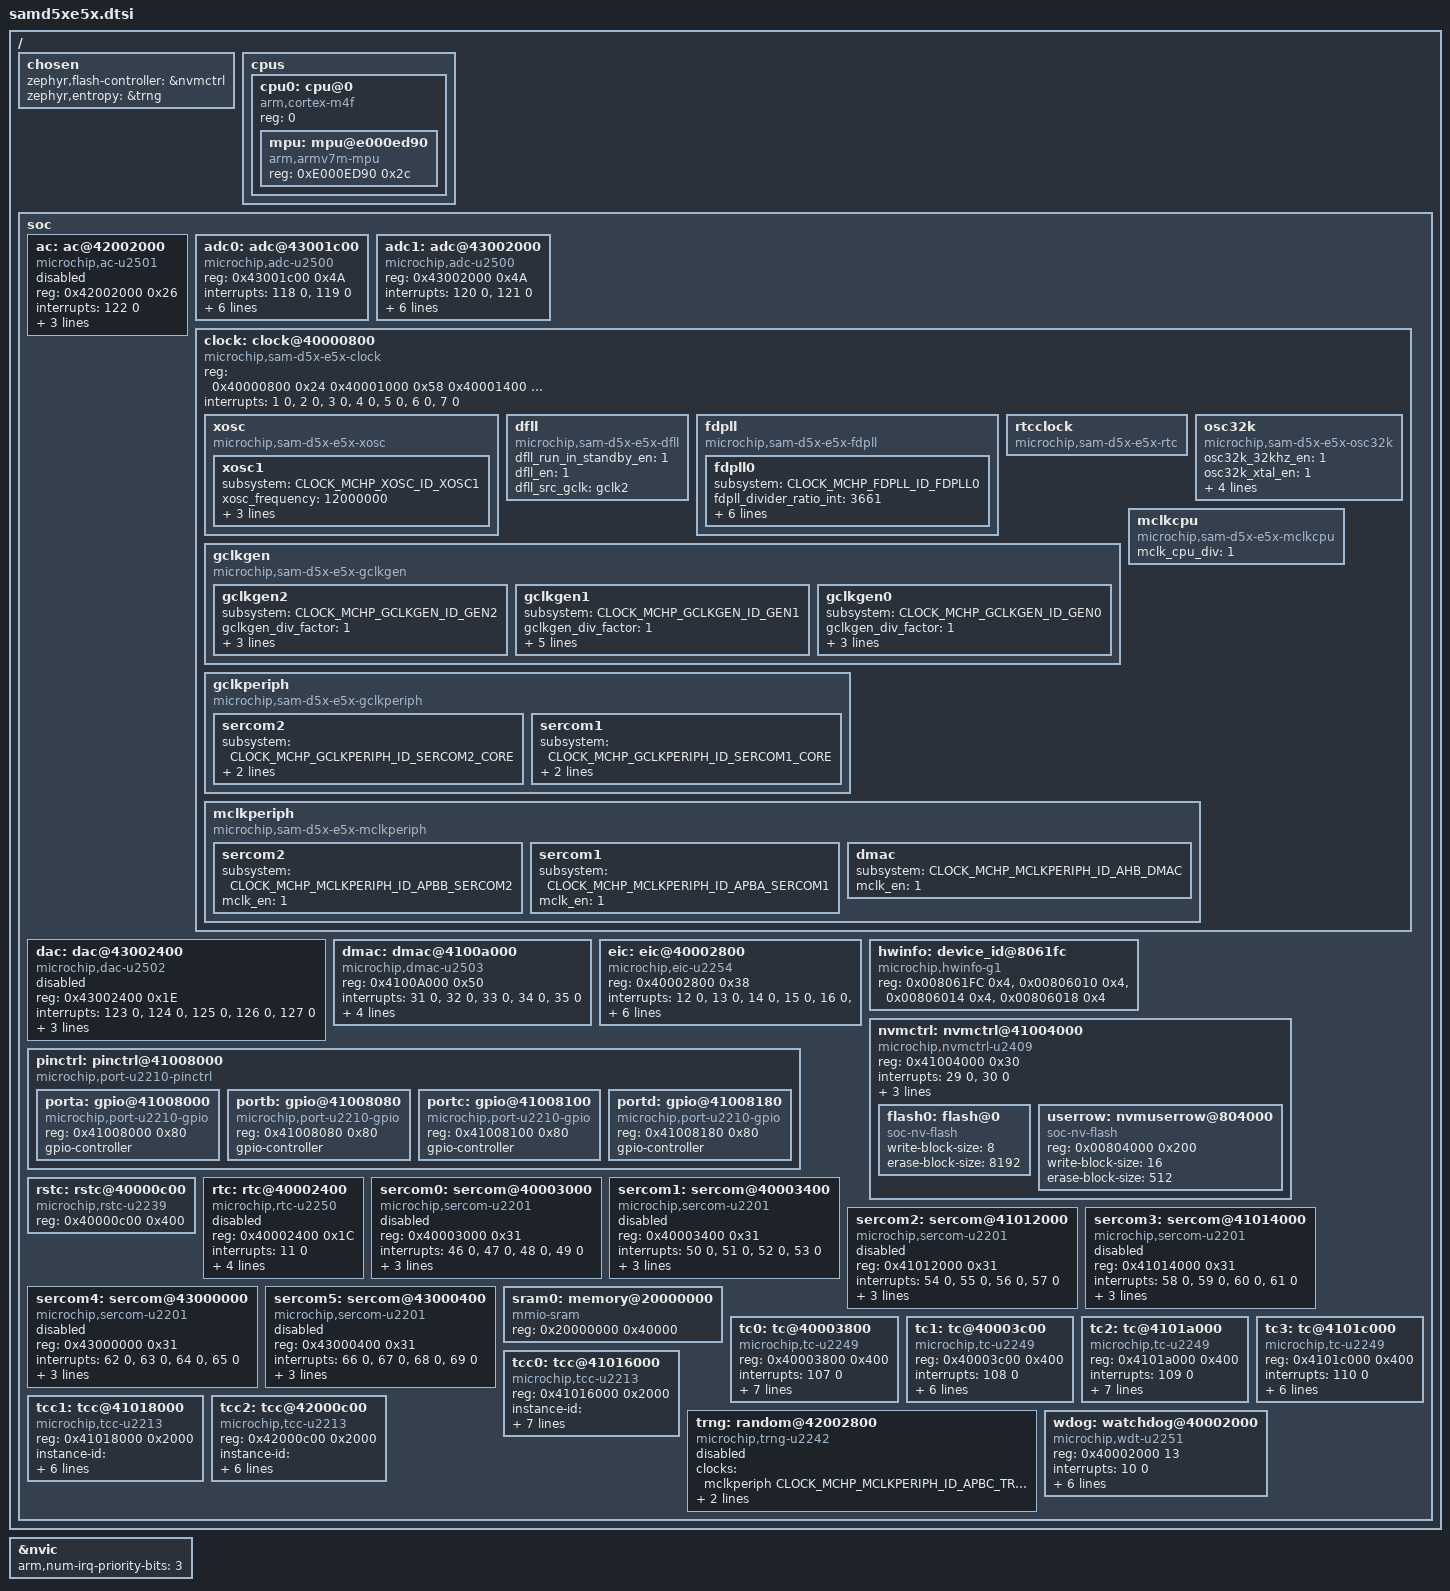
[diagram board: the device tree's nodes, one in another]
/*
 * Copyright (c) 2025 Microchip Technology Inc.
 *
 * SPDX-License-Identifier: Apache-2.0
 */

#include <arm/armv7-m.dtsi>
#include <zephyr/dt-bindings/adc/adc.h>
#include <zephyr/dt-bindings/gpio/gpio.h>
#include <zephyr/dt-bindings/i2c/i2c.h>
#include <zephyr/dt-bindings/pwm/pwm.h>
#include <zephyr/dt-bindings/pwm/mchp_pwm_sam_d5x_e5x.h>
#include <zephyr/dt-bindings/clock/mchp_sam_d5x_e5x_clock.h>
/ {
	chosen {
		zephyr,flash-controller = &nvmctrl;
		zephyr,entropy = &trng;
	};
	cpus {
		#address-cells = <1>;
		#size-cells = <0>;
		cpu0: cpu@0 {
			device_type = "cpu";
			compatible = "arm,cortex-m4f";
			reg = <0>;
			#address-cells = <1>;
			#size-cells = <1>;
			mpu: mpu@e000ed90 {
				compatible = "arm,armv7m-mpu";
				reg = <0xE000ED90 0x2c>;
			};
		};
	};
	/* Child nodes inside this block are arranged alphabetically */
	soc {
		ac: ac@42002000 {
			compatible = "microchip,ac-u2501";
			status = "disabled";
			reg = <0x42002000 0x26>;
			interrupts = <122 0>;
			clocks = <&mclkperiph CLOCK_MCHP_MCLKPERIPH_ID_APBC_AC>,
					<&gclkperiph CLOCK_MCHP_GCLKPERIPH_ID_AC>;
			clock-names = "mclk", "gclk";
		};
		adc0: adc@43001c00 {
			compatible = "microchip,adc-u2500";
			reg = <0x43001c00 0x4A>;
			interrupts = <118 0>, <119 0>;
			interrupt-names = "overrun", "resrdy";
			/*
			 * 16 MHz max, source clock must not exceed 100 MHz.
			 * -> 48 MHz GCLK(2) / 4 = 12 MHz
			 */
			prescaler = <4>;
			num-channels = <23>;
			/* Internal Bandgap reference voltage */
			vref-mv = <2400>;
			#io-channel-cells = <1>;
			clocks = <&mclkperiph CLOCK_MCHP_MCLKPERIPH_ID_APBD_ADC0>,
					<&gclkperiph CLOCK_MCHP_GCLKPERIPH_ID_ADC0>;
			clock-names = "MCLK", "GCLK";
		};
		adc1: adc@43002000 {
			compatible = "microchip,adc-u2500";
			reg = <0x43002000 0x4A>;
			interrupts = <120 0>, <121 0>;
			interrupt-names = "overrun", "resrdy";
			/*
			 * 16 MHz max, source clock must not exceed 100 MHz.
			 * -> 48 MHz GCLK(2) / 4 = 12 MHz
			 */
			prescaler = <4>;
			num-channels = <23>;
			/* Internal Bandgap reference voltage */
			vref-mv = <2400>;
			#io-channel-cells = <1>;
			clocks = <&mclkperiph CLOCK_MCHP_MCLKPERIPH_ID_APBD_ADC1>,
					<&gclkperiph CLOCK_MCHP_GCLKPERIPH_ID_ADC1>;
			clock-names = "MCLK", "GCLK";
		};
		clock: clock@40000800 {
			compatible = "microchip,sam-d5x-e5x-clock";
			reg =	<
					0x40000800 0x24
					0x40001000 0x58
					0x40001400 0x20
					0x40001c00 0x140>; // mclk, oscctrl, osc32kctrl, gclk
			interrupts = <1 0>, <2 0>, <3 0>, <4 0>, <5 0>, <6 0>, <7 0>;

			xosc: xosc {
				compatible = "microchip,sam-d5x-e5x-xosc";
				xosc1 {
					subsystem = <CLOCK_MCHP_XOSC_ID_XOSC1>;
					xosc_frequency = <12000000>;
					xosc_en = <1>;
					xosc_xtal_en = <1>;
					xosc_run_in_standby_en = <1>;
				};
			};
			dfll: dfll {
				compatible = "microchip,sam-d5x-e5x-dfll";
				dfll_run_in_standby_en = <1>;
				dfll_en = <1>;
				dfll_src_gclk = "gclk2";
			};
			fdpll: fdpll {
				compatible = "microchip,sam-d5x-e5x-fdpll";
				fdpll0 {
					subsystem = <CLOCK_MCHP_FDPLL_ID_FDPLL0>;
					fdpll_divider_ratio_int = <3661>;
					fdpll_divider_ratio_frac = <3>;
					fdpll_src = "gclk2";
					fdpll_lock_bypass_en = <1>;
					fdpll_run_in_standby_en = <0>;
					fdpll_en = <1>;
					fdpll_wakeup_fast_en = <1>;
				};
			};
			rtcclock: rtcclock {
				compatible = "microchip,sam-d5x-e5x-rtc";
				#clock-cells = <1>;
			};
			osc32k: osc32k {
				compatible = "microchip,sam-d5x-e5x-osc32k";
				osc32k_32khz_en = <1>;
				osc32k_xtal_en = <1>;
				osc32k_startup_time = <62>;
				osc32k_run_in_standby_en = <1>;
				osc32k_gain_mode = "standard";
				osc32k_en = <1>;
			};
			gclkgen: gclkgen {
				compatible = "microchip,sam-d5x-e5x-gclkgen";
				gclkgen2 {
					subsystem = <CLOCK_MCHP_GCLKGEN_ID_GEN2>;
					gclkgen_div_factor = <1>;
					gclkgen_run_in_standby_en = <1>;
					gclkgen_src = "osc32k";
					gclkgen_en = <1>;
				};
				gclkgen1 {
					subsystem = <CLOCK_MCHP_GCLKGEN_ID_GEN1>;
					gclkgen_div_factor = <1>;
					gclkgen_run_in_standby_en = <1>;
					gclkgen_pin_output_en = <1>;
					gclkgen_src = "xosc1";
					gclkgen_duty_50_50_en = <1>;
					gclkgen_en = <1>;
				};
				gclkgen0 {
					subsystem = <CLOCK_MCHP_GCLKGEN_ID_GEN0>;
					gclkgen_div_factor = <1>;
					gclkgen_run_in_standby_en = <1>;
					gclkgen_src = "fdpll0";
					gclkgen_en = <1>;
				};
			};
			gclkperiph: gclkperiph {
				compatible = "microchip,sam-d5x-e5x-gclkperiph";
				#clock-cells = <1>;
				sercom2 {
					subsystem = <CLOCK_MCHP_GCLKPERIPH_ID_SERCOM2_CORE>;
					gclkperiph_src = "gclk0";
					gclkperiph_en = <1>;
				};
				sercom1 {
					subsystem = <CLOCK_MCHP_GCLKPERIPH_ID_SERCOM1_CORE>;
					gclkperiph_src = "gclk0";
					gclkperiph_en = <1>;
				};
			};
			mclkcpu: mclkcpu {
				compatible = "microchip,sam-d5x-e5x-mclkcpu";
				mclk_cpu_div = <1>;
			};
			mclkperiph: mclkperiph {
				compatible = "microchip,sam-d5x-e5x-mclkperiph";
				#clock-cells = <1>;
				sercom2 {
					subsystem = <CLOCK_MCHP_MCLKPERIPH_ID_APBB_SERCOM2>;
					mclk_en = <1>;
				};
				sercom1 {
					subsystem = <CLOCK_MCHP_MCLKPERIPH_ID_APBA_SERCOM1>;
					mclk_en = <1>;
				};
				dmac {
					subsystem = <CLOCK_MCHP_MCLKPERIPH_ID_AHB_DMAC>;
					mclk_en = <1>;
				};
			};
		};
		dac: dac@43002400 {
			compatible = "microchip,dac-u2502";
			status = "disabled";
			reg = <0x43002400 0x1E>;
			interrupts = <123 0>, <124 0>, <125 0>, <126 0>, <127 0>;
			#io-channel-cells = <1>;
			clocks = <&mclkperiph CLOCK_MCHP_MCLKPERIPH_ID_APBD_DAC>,
					<&gclkperiph CLOCK_MCHP_GCLKPERIPH_ID_DAC>;
			clock-names = "mclk", "gclk";
		};
		dmac: dmac@4100a000 {
			compatible = "microchip,dmac-u2503";
			reg = <0x4100A000 0x50>;
			interrupts = <31 0>, <32 0>, <33 0>, <34 0>, <35 0>;
			clocks = <&mclkperiph CLOCK_MCHP_MCLKPERIPH_ID_AHB_DMAC>;
			clock-names = "mclk";
			dma-channels = <32>;
			dma-alignment = <16>;
			#dma-cells = <2>;
		};
		eic: eic@40002800 {
			compatible = "microchip,eic-u2254";
			status = "okay";
			reg = <0x40002800 0x38>;
			interrupts = <12 0>, <13 0>, <14 0>, <15 0>,
				     <16 0>, <17 0>, <18 0>, <19 0>,
				     <20 0>, <21 0>, <22 0>, <23 0>,
				     <24 0>, <25 0>, <26 0>, <27 0>;
			clocks = <&mclkperiph CLOCK_MCHP_MCLKPERIPH_ID_APBA_EIC>,
					<&gclkperiph CLOCK_MCHP_GCLKPERIPH_ID_EIC>;
			clock-names = "mclk", "gclk";
			low-power-mode;
		};
		hwinfo: device_id@8061fc {
			compatible = "microchip,hwinfo-g1";
			reg =	<0x008061FC 0x4>,
				<0x00806010 0x4>,
				<0x00806014 0x4>,
				<0x00806018 0x4>;
		};
		nvmctrl: nvmctrl@41004000 {
			compatible = "microchip,nvmctrl-u2409";
			status = "okay";
			reg = <0x41004000 0x30>;
			interrupts = <29 0>, <30 0>;
			clocks = <&mclkperiph CLOCK_MCHP_MCLKPERIPH_ID_APBB_NVMCTRL>;
			clock-names = "mclk";
			lock-regions = <32>;
			#address-cells = <1>;
			#size-cells = <1>;
			flash0: flash@0 {
				compatible = "soc-nv-flash";
				write-block-size = <8>;
				erase-block-size = <8192>;
			};
		    userrow: nvmuserrow@804000 {
				compatible = "soc-nv-flash";
				reg = <0x00804000 0x200>;
				write-block-size = <16>;
				erase-block-size = <512>;
			};
		};
		pinctrl: pinctrl@41008000 {
			compatible = "microchip,port-u2210-pinctrl";
			#address-cells = <1>;
			#size-cells = <1>;
			ranges = <0x41008000 0x41008000 0x200>;
			porta: gpio@41008000 {
				compatible = "microchip,port-u2210-gpio";
				reg = <0x41008000 0x80>;
				gpio-controller;
				#gpio-cells = <2>;
				#microchip,pin-cells = <2>;
			};
			portb: gpio@41008080 {
				compatible = "microchip,port-u2210-gpio";
				reg = <0x41008080 0x80>;
				gpio-controller;
				#gpio-cells = <2>;
				#microchip,pin-cells = <2>;
			};
			portc: gpio@41008100 {
				compatible = "microchip,port-u2210-gpio";
				reg = <0x41008100 0x80>;
				gpio-controller;
				#gpio-cells = <2>;
				#microchip,pin-cells = <2>;
			};
			portd: gpio@41008180 {
				compatible = "microchip,port-u2210-gpio";
				reg = <0x41008180 0x80>;
				gpio-controller;
				#gpio-cells = <2>;
				#microchip,pin-cells = <2>;
			};
		};
		rstc: rstc@40000c00 {
			compatible = "microchip,rstc-u2239";
			status = "okay";
			reg = <0x40000c00 0x400>;
		};
		rtc: rtc@40002400 {
			compatible = "microchip,rtc-u2250";
			status = "disabled";
			reg = <0x40002400 0x1C>;
			interrupts = <11 0>;
			clocks = <&mclkperiph CLOCK_MCHP_MCLKPERIPH_ID_APBA_RTC>,
					<&rtcclock CLOCK_MCHP_RTC_ID>;
			clock-names = "mclk", "rtcclk";
			prescaler = <1>;
		};
		sercom0: sercom@40003000 {
			compatible = "microchip,sercom-u2201";
			status = "disabled";
			reg = <0x40003000 0x31>;
			interrupts = <46 0>, <47 0>, <48 0>, <49 0>;
			clocks = <&mclkperiph CLOCK_MCHP_MCLKPERIPH_ID_APBA_SERCOM0>,
					<&gclkperiph CLOCK_MCHP_GCLKPERIPH_ID_SERCOM0_CORE>;
			clock-names = "mclk", "gclk";
		};
		sercom1: sercom@40003400 {
			compatible = "microchip,sercom-u2201";
			status = "disabled";
			reg = <0x40003400 0x31>;
			interrupts = <50 0>, <51 0>, <52 0>, <53 0>;
			clocks = <&mclkperiph CLOCK_MCHP_MCLKPERIPH_ID_APBA_SERCOM1>,
					<&gclkperiph CLOCK_MCHP_GCLKPERIPH_ID_SERCOM1_CORE>;
			clock-names = "mclk", "gclk";
		};
		sercom2: sercom@41012000 {
			compatible = "microchip,sercom-u2201";
			status = "disabled";
			reg = <0x41012000 0x31>;
			interrupts = <54 0>, <55 0>, <56 0>, <57 0>;
			clocks = <&mclkperiph CLOCK_MCHP_MCLKPERIPH_ID_APBB_SERCOM2>,
					<&gclkperiph CLOCK_MCHP_GCLKPERIPH_ID_SERCOM2_CORE>;
			clock-names = "mclk", "gclk";
		};
		sercom3: sercom@41014000 {
			compatible = "microchip,sercom-u2201";
			status = "disabled";
			reg = <0x41014000 0x31>;
			interrupts = <58 0>, <59 0>, <60 0>, <61 0>;
			clocks = <&mclkperiph CLOCK_MCHP_MCLKPERIPH_ID_APBB_SERCOM3>,
					<&gclkperiph CLOCK_MCHP_GCLKPERIPH_ID_SERCOM3_CORE>;
			clock-names = "mclk", "gclk";
		};
		sercom4: sercom@43000000 {
			compatible = "microchip,sercom-u2201";
			status = "disabled";
			reg = <0x43000000 0x31>;
			interrupts = <62 0>, <63 0>, <64 0>, <65 0>;
			clocks = <&mclkperiph CLOCK_MCHP_MCLKPERIPH_ID_APBD_SERCOM4>,
					<&gclkperiph CLOCK_MCHP_GCLKPERIPH_ID_SERCOM4_CORE>;
			clock-names = "mclk", "gclk";
		};
		sercom5: sercom@43000400 {
			compatible = "microchip,sercom-u2201";
			status = "disabled";
			reg = <0x43000400 0x31>;
			interrupts = <66 0>, <67 0>, <68 0>, <69 0>;
			clocks = <&mclkperiph CLOCK_MCHP_MCLKPERIPH_ID_APBD_SERCOM5>,
					<&gclkperiph CLOCK_MCHP_GCLKPERIPH_ID_SERCOM5_CORE>;
			clock-names = "mclk", "gclk";
		};
		sram0: memory@20000000 {
			compatible = "mmio-sram";
			reg = <0x20000000 0x40000>;
		};
		tc0: tc@40003800 {
			compatible = "microchip,tc-u2249";
			reg = <0x40003800 0x400>;
			interrupts = <107 0>;
			instance-id = <PWM_COUNTER_MCHP_SAM_D5X_E5X_TC0_ID>;
			clocks = <&mclkperiph CLOCK_MCHP_MCLKPERIPH_ID_APBA_TC0>,
					<&gclkperiph CLOCK_MCHP_GCLKPERIPH_ID_TC0>;

			clock-names = "mclk", "gclk";
			prescaler = <1>;
			client = <&tc1>;
		};
		tc1: tc@40003c00 {
			compatible = "microchip,tc-u2249";
			reg = <0x40003c00 0x400>;
			interrupts = <108 0>;
			instance-id = <PWM_COUNTER_MCHP_SAM_D5X_E5X_TC1_ID>;
			clocks = <&mclkperiph CLOCK_MCHP_MCLKPERIPH_ID_APBA_TC1>,
					<&gclkperiph CLOCK_MCHP_GCLKPERIPH_ID_TC1>;

			clock-names = "mclk", "gclk";
			prescaler = <1>;
		};
		tc2: tc@4101a000 {
			compatible = "microchip,tc-u2249";
			reg = <0x4101a000 0x400>;
			interrupts = <109 0>;
			instance-id = <PWM_COUNTER_MCHP_SAM_D5X_E5X_TC2_ID>;
			clocks = <&mclkperiph CLOCK_MCHP_MCLKPERIPH_ID_APBB_TC2>,
					<&gclkperiph CLOCK_MCHP_GCLKPERIPH_ID_TC2>;
			clock-names = "mclk", "gclk";
			prescaler = <1>;
			client = <&tc3>;

		};
		tc3: tc@4101c000 {
			compatible = "microchip,tc-u2249";
			reg = <0x4101c000 0x400>;
			interrupts = <110 0>;
			instance-id = <PWM_COUNTER_MCHP_SAM_D5X_E5X_TC3_ID>;
			clocks = <&mclkperiph CLOCK_MCHP_MCLKPERIPH_ID_APBB_TC3>,
					<&gclkperiph CLOCK_MCHP_GCLKPERIPH_ID_TC3>;
			clock-names = "mclk", "gclk";
			prescaler = <1>;
		};
		tcc0: tcc@41016000 {
			compatible = "microchip,tcc-u2213";
			reg = <0x41016000 0x2000>;
			instance-id = <PWM_COUNTER_MCHP_SAM_D5X_E5X_TCC0_ID>;
			interrupts = <85 0>, <86 0>, <87 0>, <88 0>, <89 0>,
			<90 0>, <91 0>;
			clocks = <&mclkperiph CLOCK_MCHP_MCLKPERIPH_ID_APBB_TCC0>,
					<&gclkperiph CLOCK_MCHP_GCLKPERIPH_ID_TCC0>;
			clock-names = "mclk", "gclk";
			prescaler = <1>;
		};
		tcc1: tcc@41018000 {
			compatible = "microchip,tcc-u2213";
			reg = <0x41018000 0x2000>;
			instance-id = <PWM_COUNTER_MCHP_SAM_D5X_E5X_TCC1_ID>;
			interrupts = <92 0>, <93 0>, <94 0>, <95 0>, <96 0>;
			clocks = <&mclkperiph CLOCK_MCHP_MCLKPERIPH_ID_APBB_TCC1>,
					<&gclkperiph CLOCK_MCHP_GCLKPERIPH_ID_TCC1>;
			clock-names = "mclk", "gclk";
			prescaler = <1>;
		};
		tcc2: tcc@42000c00 {
			compatible = "microchip,tcc-u2213";
			reg = <0x42000c00 0x2000>;
			instance-id = <PWM_COUNTER_MCHP_SAM_D5X_E5X_TCC2_ID >;
			interrupts = <97 0>, <98 0>, <99 0>, <100 0>;
			clocks = <&mclkperiph CLOCK_MCHP_MCLKPERIPH_ID_APBC_TCC2>,
					<&gclkperiph CLOCK_MCHP_GCLKPERIPH_ID_TCC2>;
			clock-names = "mclk", "gclk";
			prescaler = <1>;
		};
		trng: random@42002800 {
			compatible = "microchip,trng-u2242";
			status = "disabled";
			clocks = <&mclkperiph CLOCK_MCHP_MCLKPERIPH_ID_APBC_TRNG>;
			clock-names = "mclk";
			reg = <0x42002800 0x1e>;
			interrupts = <131 0>;
		};

		wdog: watchdog@40002000 {
			compatible = "microchip,wdt-u2251";
			reg = <0x40002000 13>;
			interrupts = <10 0>;
			clocks = <&mclkperiph CLOCK_MCHP_MCLKPERIPH_ID_APBA_WDT>;
			clock-names = "mclk";
			max_installable_timeout_count = <1>;
			max_timeout_window = <0x4000>;    /**< 16384 milliseconds */
			max_timeout_window_mode = <0x8000>;/**< 32768 milliseconds */
			min_window_limit = <0x8>;/**< 8 milliseconds */
		};
	};
};
&nvic {
	arm,num-irq-priority-bits = <3>;
};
